VERSION ""

NS_ :

BS_:

BU_: FCMS
VAL_TABLE_ FMS_PushButtonStates 1 "On" 0 "Off" ;
VAL_TABLE_ FMS_SSM 3 "Failure Warning " 2 "Functional Test" 1 "NCD" 0 "Normal Operation " ;
VAL_TABLE_ FMS_SDI 2 "Computer 2" 1 "Computer 1" ;
VAL_TABLE_ FMS_Pump_States 1 "Off" 0 "Energized" ;
VAL_TABLE_ vt_BNRaccuracy 1 "Degraded Accuracy" 0 "Nominal Accuracy" ;
VAL_TABLE_ vt_BCDstatus_above_below 3 "Below" 2 "FT (functional test)" 1 "NCD (no computed data)" 0 "Above" ;
VAL_TABLE_ vt_BCDstatus_to_from 3 "From" 2 "FT (functional test)" 1 "NCD (no computed data)" 0 "To" ;
VAL_TABLE_ vt_BCDstatus_right_left 3 "Left" 2 "FT (functional test)" 1 "NCD (no computed data)" 0 "Right" ;
VAL_TABLE_ vt_BCDstatus_east_west 3 "West" 2 "FT (functional test)" 1 "NCD (no computed data)" 0 "East" ;
VAL_TABLE_ vt_BCDstatus_north_south 3 "South" 2 "FT (functional test)" 1 "NCD (no computed data)" 0 "North" ;
VAL_TABLE_ vt_BCDstatus_plus_minus 3 "Minus" 2 "FT (functional test)" 1 "NCD (no computed data)" 0 "Plus" ;
VAL_TABLE_ vt_DSCstatus 3 "FW (failure warning)" 2 "FT (functional test)" 1 "NCD (no computed data)" 0 "NO (normal operation)" ;
VAL_TABLE_ vt_BNRsign_above_below 1 "Below" 0 "Above" ;
VAL_TABLE_ vt_BNRsign_to_from 1 "From" 0 "To" ;
VAL_TABLE_ vt_BNRsign_right_left 1 "Left" 0 "Right" ;
VAL_TABLE_ vt_BNRsign_east_west 1 "West" 0 "East" ;
VAL_TABLE_ vt_BNRsign_north_south 1 "South" 0 "North" ;
VAL_TABLE_ vt_BNRsign_plus_minus 1 "Minus" 0 "Plus" ;
VAL_TABLE_ vt_BNRstatus 3 "NO (normal operation)" 2 "FT (functional test)" 1 "NCD (no computed data)" 0 "FW (failure warning)" ;

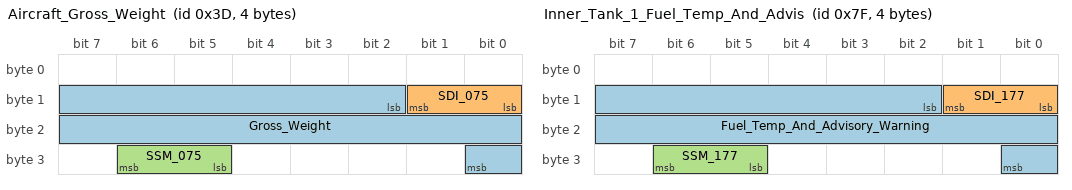
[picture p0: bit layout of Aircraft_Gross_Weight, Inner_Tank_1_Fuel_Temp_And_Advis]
BO_ 61 Aircraft_Gross_Weight: 4 FCMS
 SG_ Gross_Weight : 10|15@1+ (40,0) [0|1310720] "lbs" Vector__XXX
 SG_ SDI_075 : 8|2@1+ (1,0) [0|3] "" Vector__XXX
 SG_ SSM_075 : 29|2@1+ (1,0) [0|3] "" Vector__XXX

BO_ 96 Fuel_Pump_Contactor: 4 FCMS
 SG_ Main_Pump_1 : 11|1@1+ (1,0) [0|1] "" Vector__XXX
 SG_ Standby_Pump_1 : 10|1@1+ (1,0) [0|1] "" Vector__XXX
 SG_ Standby_Pump_2 : 12|1@1+ (1,0) [0|1] "" Vector__XXX
 SG_ Main_Pump_2 : 13|1@1+ (1,0) [0|1] "" Vector__XXX
 SG_ SDI_140 : 8|2@1+ (1,0) [0|3] "" Vector__XXX
 SG_ SSM_140 : 29|2@1+ (1,0) [0|3] "" Vector__XXX
 SG_ Main_Pump_3 : 15|1@1+ (1,0) [0|1] "" Vector__XXX
 SG_ Main_Pump_4 : 17|1@1+ (1,0) [0|1] "" Vector__XXX
 SG_ Standby_Pump_3 : 14|1@1+ (1,0) [0|1] "" Vector__XXX
 SG_ Standby_Pump_4 : 16|1@1+ (1,0) [0|1] "" Vector__XXX
 SG_ Center_Tank_Left_Transfer_Pump : 18|1@1+ (1,0) [0|1] "" Vector__XXX
 SG_ Center_Tank_Right_Transfer_Pump : 19|1@1+ (1,0) [0|1] "" Vector__XXX
 SG_ Center_Tank_Left_Aft_Transfer_Pu : 20|1@1+ (1,0) [0|1] "" Vector__XXX
 SG_ Center_Tank_Right_Aft_Transfer_P : 21|1@1+ (1,0) [0|1] "" Vector__XXX
 SG_ Act_Transfer_Pump : 22|1@1+ (1,0) [0|1] "" Vector__XXX
 SG_ Trim_Tank_Left_Transfer_Pump : 23|1@1+ (1,0) [0|1] "" Vector__XXX
 SG_ Trim_Tank_Right_Transfer_Pump : 24|1@1+ (1,0) [0|1] "" Vector__XXX
 SG_ Inner_1_Tank_Aft_Transfer_Pump : 25|1@1+ (1,0) [0|1] "" Vector__XXX
 SG_ Inner_2_Tank_Aft_Transfer_Pump : 26|1@1+ (1,0) [0|1] "" Vector__XXX
 SG_ Inner_3_Tank_Aft_Transfer_Pump : 27|1@1+ (1,0) [0|1] "" Vector__XXX
 SG_ Inner_4_Tank_Aft_Transfer_Pump : 28|1@1+ (1,0) [0|1] "" Vector__XXX

BO_ 127 Inner_Tank_1_Fuel_Temp_And_Advis: 4 Vector__XXX
 SG_ Fuel_Temp_And_Advisory_Warning : 10|15@1- (0.25,0) [-512|512] ""  FCMS
 SG_ SDI_177 : 8|2@1+ (1,0) [0|3] ""  FCMS
 SG_ SSM_177 : 29|2@1+ (1,0) [0|3] ""  FCMS

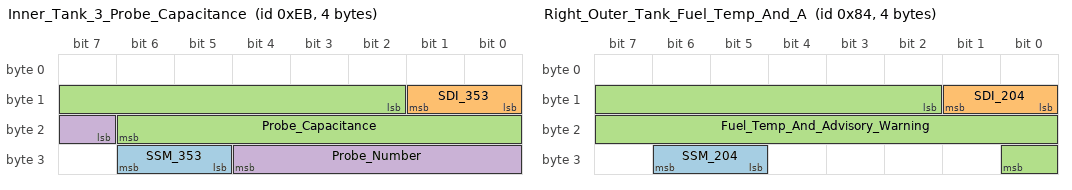
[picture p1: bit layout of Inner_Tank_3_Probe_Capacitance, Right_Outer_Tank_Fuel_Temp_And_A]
BO_ 235 Inner_Tank_3_Probe_Capacitance: 4 Vector__XXX
 SG_ SSM_353 : 29|2@1+ (1,0) [0|3] ""  FCMS
 SG_ SDI_353 : 8|2@1+ (1,0) [0|3] ""  FCMS
 SG_ Probe_Capacitance : 10|13@1- (1,0) [0|400] ""  FCMS
 SG_ Probe_Number : 23|6@1- (1,0) [0|30] ""  FCMS

BO_ 107 Level_States: 4 FCMS
 SG_ Act1_High_Level : 24|1@1+ (1,0) [0|1] "" Vector__XXX
 SG_ Act1_Low_Level : 25|1@1+ (1,0) [0|1] "" Vector__XXX
 SG_ Act2_High_Level : 26|1@1+ (1,0) [0|1] "" Vector__XXX
 SG_ Act2_Low_Level : 27|1@1+ (1,0) [0|1] "" Vector__XXX
 SG_ Center_Tank_High_Level : 17|1@1+ (1,0) [0|1] "" Vector__XXX
 SG_ Center_Tank_Low_Level : 16|1@1+ (1,0) [0|1] "" Vector__XXX
 SG_ Inner_Tank_1_High_Level : 12|1@1+ (1,0) [0|1] "" Vector__XXX
 SG_ Inner_Tank_1_Low_Level : 13|1@1+ (1,0) [0|1] "" Vector__XXX
 SG_ Inner_Tank_2_High_Level : 14|1@1+ (1,0) [0|1] "" Vector__XXX
 SG_ Inner_Tank_2_Low_Level : 15|1@1+ (1,0) [0|1] "" Vector__XXX
 SG_ Inner_Tank_3_High_Level : 18|1@1+ (1,0) [0|1] "" Vector__XXX
 SG_ Inner_Tank_3_Low_Level : 20|1@1+ (1,0) [0|1] "" Vector__XXX
 SG_ Inner_Tank_4_High_Level : 19|1@1+ (1,0) [0|1] "" Vector__XXX
 SG_ Inner_Tank_4_Low_Level : 21|1@1+ (1,0) [0|1] "" Vector__XXX
 SG_ Left_Outer_High_Level : 11|1@1+ (1,0) [0|1] "" Vector__XXX
 SG_ Left_Surge_Tank : 10|1@1+ (1,0) [0|1] "" Vector__XXX
 SG_ PAD : 28|1@1+ (1,0) [0|1] "" Vector__XXX
 SG_ Right_Outer_High_Level : 22|1@1+ (1,0) [0|1] "" Vector__XXX
 SG_ Right_Surge_Tank : 23|1@1+ (1,0) [0|1] "" Vector__XXX
 SG_ SDI_153 : 8|2@1+ (1,0) [0|3] "" Vector__XXX
 SG_ SSM_153 : 29|2@1+ (1,0) [0|3] "" Vector__XXX

BO_ 97 Pump_Contactor_And_Pushbutton_St: 4 FCMS
 SG_ Center_Tank_Right_Transfer_Pump_ : 22|1@1+ (1,0) [0|1] ""  FCMS
 SG_ Center_Tank_Left_Aft_Transf_0000 : 23|1@1+ (1,0) [0|1] ""  FCMS
 SG_ Center_Tank_Right_Aft_Trans_0000 : 24|1@1+ (1,0) [0|1] ""  FCMS
 SG_ Trim_Tank_Left_Transfer_Pump_Pus : 25|1@1+ (1,0) [0|1] ""  FCMS
 SG_ Trim_Tank_Right_Transfer_Pump_Pu : 26|1@1+ (1,0) [0|1] ""  FCMS
 SG_ RCT_Transfer_Pump_A_Front_Pushbu : 27|1@1+ (1,0) [0|1] ""  FCMS
 SG_ RCT_Transfer_Pump_B_Rear_Pushbut : 28|1@1+ (1,0) [0|1] ""  FCMS
 SG_ Main_Pump_1_Pushbutton : 13|1@1+ (1,0) [0|1] ""  FCMS
 SG_ Main_Pump_2_Pushbutton : 15|1@1+ (1,0) [0|1] ""  FCMS
 SG_ Main_Pump_3_Pushbutton : 17|1@1+ (1,0) [0|1] ""  FCMS
 SG_ Main_Pump_4_Pushbutton : 19|1@1+ (1,0) [0|1] ""  FCMS
 SG_ RCT_Transfer_Pump_A_Front_Contac : 10|1@1+ (1,0) [0|1] ""  FCMS
 SG_ RCT_Transfer_Pump_B_Rear_Contact : 11|1@1+ (1,0) [0|1] ""  FCMS
 SG_ Center_Tank_Left_Transfer_Pump_P : 21|1@1+ (1,0) [0|1] ""  FCMS
 SG_ APU_Pump_Contactor : 12|1@1+ (1,0) [0|1] ""  FCMS
 SG_ Standby_Pump_2_Pushbutton : 16|1@1+ (1,0) [0|1] ""  FCMS
 SG_ Standby_Pump_3_Pushbutton : 18|1@1+ (1,0) [0|1] ""  FCMS
 SG_ Standby_Pump_4_Pushbutton : 20|1@1+ (1,0) [0|1] ""  FCMS
 SG_ Standby_Pump_1_Pushbutton : 14|1@1+ (1,0) [0|1] ""  FCMS
 SG_ SDI_141 : 8|2@1+ (1,0) [0|3] ""  FCMS
 SG_ SSM_141 : 29|2@1+ (1,0) [0|3] ""  FCMS

BO_ 132 Right_Outer_Tank_Fuel_Temp_And_A: 4 Vector__XXX
 SG_ SSM_204 : 29|2@1+ (1,0) [0|3] ""  FCMS
 SG_ SDI_204 : 8|2@1+ (1,0) [0|3] ""  FCMS
 SG_ Fuel_Temp_And_Advisory_Warning : 10|15@1- (0.25,0) [-512|512] ""  FCMS

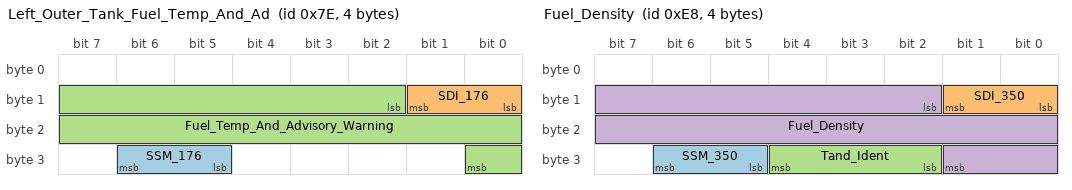
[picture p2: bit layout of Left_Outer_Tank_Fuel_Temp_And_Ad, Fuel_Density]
BO_ 126 Left_Outer_Tank_Fuel_Temp_And_Ad: 4 Vector__XXX
 SG_ SSM_176 : 29|2@1+ (1,0) [0|3] ""  FCMS
 SG_ SDI_176 : 8|2@1+ (1,0) [0|3] ""  FCMS
 SG_ Fuel_Temp_And_Advisory_Warning : 10|15@1- (0.25,0) [-512|512] ""  FCMS

BO_ 232 Fuel_Density: 4 Vector__XXX
 SG_ SSM_350 : 29|2@1+ (1,0) [0|3] ""  FCMS
 SG_ SDI_350 : 8|2@1+ (1,0) [0|3] ""  FCMS
 SG_ Tand_Ident : 26|3@1+ (1,0) [0|7] ""  FCMS
 SG_ Fuel_Density : 10|16@1- (1,0) [0|1] "kg/l"  FCMS

CM_ SG_ 61 SDI_075 "Source/Destination Identifier";
CM_ SG_ 96 SDI_140 "Source/Destination Identifier";
CM_ SG_ 127 SDI_177 "Source/Destination Identifier";
CM_ SG_ 235 SDI_353 "Source/Destination Identifier";
CM_ SG_ 107 SDI_153 "Source/Destination Identifier";
CM_ SG_ 97 SDI_141 "Source/Destination Identifier";
CM_ SG_ 132 SDI_204 "Source/Destination Identifier";
CM_ SG_ 126 SDI_176 "Source/Destination Identifier";
CM_ SG_ 232 SDI_350 "Source/Destination Identifier";
BA_DEF_  "ProtocolType" STRING ;
BA_DEF_ BO_  "A429SpecSource" ENUM  "ARINC","GAMA","Private";
BA_DEF_ BO_  "A429Protocol" ENUM  "BC","AIM","A619","WB1","WB2","WB3";
BA_DEF_ SG_  "A429SignalType" ENUM  "none","BCD","BNR","DISCRETE","ISO-5","SSM","SDI";
BA_DEF_  "A429Parity" ENUM  "unknown","odd","even";
BA_DEF_ BO_  "A429EquipmentId" HEX 0 4095;
BA_DEF_ BO_  "A429CycleMax" INT 0 0;
BA_DEF_ BO_  "A429Cycle" INT 0 0;
BA_DEF_ BO_  "A429CycleMin" INT 0 0;
BA_DEF_ BU_  "A429Equipment" STRING ;
BA_DEF_  "Baudrate" INT 10500 110000;
BA_DEF_  "ToolName" STRING ;
BA_DEF_  "ToolVersion" STRING ;
BA_DEF_  "Manufacturer" STRING ;
BA_DEF_  "VersionDay" INT 0 31;
BA_DEF_  "VersionMonth" INT 0 12;
BA_DEF_  "VersionWeek" INT 0 0;
BA_DEF_  "BusType" STRING ;
BA_DEF_ SG_  "SystemSignalLongSymbol" STRING ;
BA_DEF_ BO_  "SystemMessageLongSymbol" STRING ;
BA_DEF_DEF_  "ProtocolType" "Aerospace";
BA_DEF_DEF_  "A429SpecSource" "ARINC";
BA_DEF_DEF_  "A429Protocol" "BC";
BA_DEF_DEF_  "A429SignalType" "BNR";
BA_DEF_DEF_  "A429Parity" "odd";
BA_DEF_DEF_  "A429EquipmentId" 0;
BA_DEF_DEF_  "A429CycleMax" 0;
BA_DEF_DEF_  "A429Cycle" 0;
BA_DEF_DEF_  "A429CycleMin" 0;
BA_DEF_DEF_  "A429Equipment" "<unknown>";
BA_DEF_DEF_  "Baudrate" 100000;
BA_DEF_DEF_  "ToolName" "manually";
BA_DEF_DEF_  "ToolVersion" "x.y.z.n";
BA_DEF_DEF_  "Manufacturer" "<unknown>";
BA_DEF_DEF_  "VersionDay" 1;
BA_DEF_DEF_  "VersionMonth" 1;
BA_DEF_DEF_  "VersionWeek" 1;
BA_DEF_DEF_  "BusType" "ARINC429";
BA_DEF_DEF_  "SystemSignalLongSymbol" "";
BA_DEF_DEF_  "SystemMessageLongSymbol" "";
BA_ "A429Equipment" BU_ FCMS "114";
BA_ "A429EquipmentId" BO_ 61 276;
BA_ "A429CycleMax" BO_ 61 400000;
BA_ "A429CycleMin" BO_ 61 100000;
BA_ "A429Cycle" BO_ 61 200000;
BA_ "A429CycleMax" BO_ 96 400000;
BA_ "A429Cycle" BO_ 96 200000;
BA_ "A429CycleMin" BO_ 96 100000;
BA_ "SystemMessageLongSymbol" BO_ 127 "Inner_Tank_1_Fuel_Temp_And_Advisory_Warning";
BA_ "A429CycleMax" BO_ 107 400000;
BA_ "A429Cycle" BO_ 107 200000;
BA_ "A429CycleMin" BO_ 107 100000;
BA_ "A429CycleMax" BO_ 97 400000;
BA_ "A429Cycle" BO_ 97 200000;
BA_ "A429CycleMin" BO_ 97 100000;
BA_ "SystemMessageLongSymbol" BO_ 97 "Pump_Contactor_And_Pushbutton_States";
BA_ "SystemMessageLongSymbol" BO_ 132 "Right_Outer_Tank_Fuel_Temp_And_Advisory_Warning";
BA_ "SystemMessageLongSymbol" BO_ 126 "Left_Outer_Tank_Fuel_Temp_And_Advisory_Warning";
BA_ "A429EquipmentId" BO_ 232 276;
BA_ "SystemSignalLongSymbol" SG_ 96 Center_Tank_Left_Aft_Transfer_Pu "Center_Tank_Left_Aft_Transfer_Pump";
BA_ "SystemSignalLongSymbol" SG_ 96 Center_Tank_Right_Aft_Transfer_P "Center_Tank_Right_Aft_Transfer_Pump";
BA_ "SystemSignalLongSymbol" SG_ 97 Center_Tank_Right_Transfer_Pump_ "Center_Tank_Right_Transfer_Pump_Pushbutton";
BA_ "SystemSignalLongSymbol" SG_ 97 Center_Tank_Left_Aft_Transf_0000 "Center_Tank_Left_Aft_Transfer_Pump_PSHBTN";
BA_ "SystemSignalLongSymbol" SG_ 97 Center_Tank_Right_Aft_Trans_0000 "Center_Tank_Right_Aft_Transfer_Pump_PSHBTN";
BA_ "SystemSignalLongSymbol" SG_ 97 Trim_Tank_Left_Transfer_Pump_Pus "Trim_Tank_Left_Transfer_Pump_Pushbutton";
BA_ "SystemSignalLongSymbol" SG_ 97 Trim_Tank_Right_Transfer_Pump_Pu "Trim_Tank_Right_Transfer_Pump_Pushbutton";
BA_ "SystemSignalLongSymbol" SG_ 97 RCT_Transfer_Pump_A_Front_Pushbu "RCT_Transfer_Pump_A_Front_Pushbutton";
BA_ "SystemSignalLongSymbol" SG_ 97 RCT_Transfer_Pump_B_Rear_Pushbut "RCT_Transfer_Pump_B_Rear_Pushbutton";
BA_ "SystemSignalLongSymbol" SG_ 97 RCT_Transfer_Pump_A_Front_Contac "RCT_Transfer_Pump_A_Front_Contactor";
BA_ "SystemSignalLongSymbol" SG_ 97 RCT_Transfer_Pump_B_Rear_Contact "RCT_Transfer_Pump_B_Rear_Contactor";
BA_ "SystemSignalLongSymbol" SG_ 97 Center_Tank_Left_Transfer_Pump_P "Center_Tank_Left_Transfer_Pump_Pushbutton";
VAL_ 61 SSM_075 3 "Failure Warning " 2 "Functional Test" 1 "NCD" 0 "Normal Operation " ;
VAL_ 96 Main_Pump_1 1 "Off" 0 "Energized" ;
VAL_ 96 Standby_Pump_1 1 "Off" 0 "Energized" ;
VAL_ 96 Standby_Pump_2 1 "Off" 0 "Energized" ;
VAL_ 96 Main_Pump_2 1 "Off" 0 "Energized" ;
VAL_ 96 SDI_140 2 "Computer 2" 1 "Computer 1" ;
VAL_ 96 SSM_140 3 "Failure Warning " 2 "Functional Test" 1 "NCD" 0 "Normal Operation " ;
VAL_ 96 Main_Pump_3 1 "Off" 0 "Energized" ;
VAL_ 96 Main_Pump_4 1 "Off" 0 "Energized" ;
VAL_ 96 Standby_Pump_3 1 "Off" 0 "Energized" ;
VAL_ 96 Standby_Pump_4 1 "Off" 0 "Energized" ;
VAL_ 96 Center_Tank_Left_Transfer_Pump 1 "Off" 0 "Energized" ;
VAL_ 96 Center_Tank_Right_Transfer_Pump 1 "Off" 0 "Energized" ;
VAL_ 96 Center_Tank_Left_Aft_Transfer_Pu 1 "Off" 0 "Energized" ;
VAL_ 96 Center_Tank_Right_Aft_Transfer_P 1 "Off" 0 "Energized" ;
VAL_ 96 Act_Transfer_Pump 1 "Off" 0 "Energized" ;
VAL_ 96 Trim_Tank_Left_Transfer_Pump 1 "Off" 0 "Energized" ;
VAL_ 96 Trim_Tank_Right_Transfer_Pump 1 "Off" 0 "Energized" ;
VAL_ 96 Inner_1_Tank_Aft_Transfer_Pump 1 "Off" 0 "Energized" ;
VAL_ 96 Inner_2_Tank_Aft_Transfer_Pump 1 "Off" 0 "Energized" ;
VAL_ 96 Inner_3_Tank_Aft_Transfer_Pump 1 "Off" 0 "Energized" ;
VAL_ 96 Inner_4_Tank_Aft_Transfer_Pump 1 "Off" 0 "Energized" ;
VAL_ 127 SSM_177 3 "Failure Warning " 2 "Functional Test" 1 "NCD" 0 "Normal Operation " ;
VAL_ 235 SSM_353 3 "Failure Warning " 2 "Functional Test" 1 "NCD" 0 "Normal Operation " ;
VAL_ 107 Act1_High_Level 1 "High" 0 "Not High" ;
VAL_ 107 Act1_Low_Level 1 "Low" 0 "Not Low" ;
VAL_ 107 Act2_High_Level 1 "High" 0 "Not High" ;
VAL_ 107 Act2_Low_Level 1 "Low" 0 "Not Low" ;
VAL_ 107 Center_Tank_High_Level 1 "High" 0 "Not High" ;
VAL_ 107 Center_Tank_Low_Level 1 "Low" 0 "Not Low" ;
VAL_ 107 Inner_Tank_1_High_Level 1 "High" 0 "Not High" ;
VAL_ 107 Inner_Tank_1_Low_Level 1 "Low" 0 "Not Low" ;
VAL_ 107 Inner_Tank_2_High_Level 1 "High" 0 "Not High" ;
VAL_ 107 Inner_Tank_2_Low_Level 1 "Low" 0 "Not Low" ;
VAL_ 107 Inner_Tank_3_High_Level 1 "High" 0 "Not High" ;
VAL_ 107 Inner_Tank_3_Low_Level 1 "Low" 0 "Not Low" ;
VAL_ 107 Inner_Tank_4_High_Level 1 "High" 0 "Not High" ;
VAL_ 107 Inner_Tank_4_Low_Level 1 "Low" 0 "Not Low" ;
VAL_ 107 Left_Outer_High_Level 1 "High" 0 "Not High" ;
VAL_ 107 Left_Surge_Tank 1 "Wet" 0 "Not Wet" ;
VAL_ 107 Right_Outer_High_Level 1 "High" 0 "Not High" ;
VAL_ 107 Right_Surge_Tank 1 "Wet" 0 "Not Wet" ;
VAL_ 107 SDI_153 2 "Computer 2" 1 "Computer 1" ;
VAL_ 107 SSM_153 3 "Failure Warning " 2 "Functional Test" 1 "NCD" 0 "Normal Operation " ;
VAL_ 97 Center_Tank_Right_Transfer_Pump_ 1 "On" 0 "Off" ;
VAL_ 97 Center_Tank_Left_Aft_Transf_0000 1 "On" 0 "Off" ;
VAL_ 97 Center_Tank_Right_Aft_Trans_0000 1 "On" 0 "Off" ;
VAL_ 97 Trim_Tank_Left_Transfer_Pump_Pus 1 "On" 0 "Off" ;
VAL_ 97 Trim_Tank_Right_Transfer_Pump_Pu 1 "On" 0 "Off" ;
VAL_ 97 RCT_Transfer_Pump_A_Front_Pushbu 1 "On" 0 "Off" ;
VAL_ 97 RCT_Transfer_Pump_B_Rear_Pushbut 1 "On" 0 "Off" ;
VAL_ 97 Main_Pump_1_Pushbutton 1 "On" 0 "Off" ;
VAL_ 97 Main_Pump_2_Pushbutton 1 "On" 0 "Off" ;
VAL_ 97 Main_Pump_3_Pushbutton 1 "On" 0 "Off" ;
VAL_ 97 Main_Pump_4_Pushbutton 1 "On" 0 "Off" ;
VAL_ 97 RCT_Transfer_Pump_A_Front_Contac 1 "Off" 0 "Energized" ;
VAL_ 97 RCT_Transfer_Pump_B_Rear_Contact 1 "Off" 0 "Energized" ;
VAL_ 97 Center_Tank_Left_Transfer_Pump_P 1 "On" 0 "Off" ;
VAL_ 97 APU_Pump_Contactor 1 "Off" 0 "Energized" ;
VAL_ 97 Standby_Pump_2_Pushbutton 1 "On" 0 "Off" ;
VAL_ 97 Standby_Pump_3_Pushbutton 1 "On" 0 "Off" ;
VAL_ 97 Standby_Pump_4_Pushbutton 1 "On" 0 "Off" ;
VAL_ 97 Standby_Pump_1_Pushbutton 1 "On" 0 "Off" ;
VAL_ 97 SDI_141 2 "Computer 2" 1 "Computer 1" ;
VAL_ 97 SSM_141 3 "Failure Warning " 2 "Functional Test" 1 "NCD" 0 "Normal Operation " ;
VAL_ 132 SSM_204 3 "Failure Warning " 2 "Functional Test" 1 "NCD" 0 "Normal Operation " ;
VAL_ 126 SSM_176 3 "Failure Warning " 2 "Functional Test" 1 "NCD" 0 "Normal Operation " ;
VAL_ 232 SSM_350 3 "Failure Warning " 2 "Functional Test" 1 "NCD" 0 "Normal Operation " ;
SIG_VALTYPE_ 235 Probe_Capacitance : 2;
SIG_VALTYPE_ 235 Probe_Number : 2;
SIG_VALTYPE_ 232 Fuel_Density : 2;
